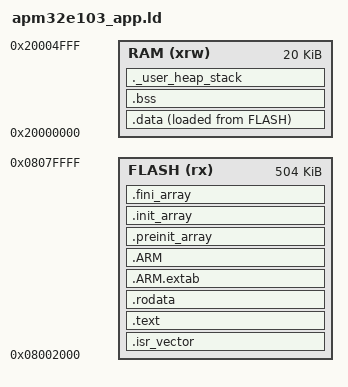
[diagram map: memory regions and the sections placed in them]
/*!
 * @file       apm32e103_app.ld
 *
 * @brief      Linker script for APM32E103CE Device
 *             Application starts at 0x08002000 (compatible with BlackMagic DFU bootloader)
 *             512KB Flash (504KB available for app), 128KB RAM
 *
 * @note       Bootloader: 0x08000000 - 0x08002000 (8KB)
 *             Application: 0x08002000 - 0x08080000 (504KB)
 */

/* Entry Point */
ENTRY(Reset_Handler)

/* Highest address of the user mode stack */
_estack = 0x20020000;    /* end of RAM (128KB) */
/* BlackMagic DFU validity check expects the initial MSP to be within 0x20000000-0x2001FFFF. */
_end_stack = 0x20004FFC; /* startup_apm32e10x_hd.S uses this value in vector table */

/* Generate a link error if heap and stack don't fit into RAM */
_Min_Heap_Size = 0x200;      /* required amount of heap  */
_Min_Stack_Size = 0x400;     /* required amount of stack */

/* Specify the memory areas */
MEMORY
{
  /* Application Flash starting at 0x08002000 (after DFU bootloader) */
  FLASH (rx)      : ORIGIN = 0x08002000, LENGTH = 504K
  RAM (xrw)       : ORIGIN = 0x20000000, LENGTH = 20K
}

/* Define output sections */
SECTIONS
{
  /* The startup code goes first into FLASH */
  .isr_vector :
  {
    . = ALIGN(4);
    /* BlackMagic DFU validates app by checking MSP word at app base address. */
    KEEP(*(.apm32_isr_vector))
    KEEP(*(.isr_vector)) /* Startup code */
    . = ALIGN(4);
  } >FLASH

  /* The program code and other data goes into FLASH */
  .text :
  {
    . = ALIGN(4);
    *(.text)           /* .text sections (code) */
    *(.text*)          /* .text* sections (code) */
    *(.glue_7)         /* glue arm to thumb code */
    *(.glue_7t)        /* glue thumb to arm code */
    *(.eh_frame)

    KEEP (*(.init))
    KEEP (*(.fini))

    . = ALIGN(4);
    _etext = .;        /* define a global symbols at end of code */
  } >FLASH

  /* Constant data goes into FLASH */
  .rodata :
  {
    . = ALIGN(4);
    *(.rodata)         /* .rodata sections (constants, strings, etc.) */
    *(.rodata*)        /* .rodata* sections (constants, strings, etc.) */
    . = ALIGN(4);
  } >FLASH

  .ARM.extab   : { *(.ARM.extab* .gnu.linkonce.armextab.*) } >FLASH
  .ARM : {
    __exidx_start = .;
    *(.ARM.exidx*)
    __exidx_end = .;
  } >FLASH

  .preinit_array     :
  {
    PROVIDE_HIDDEN (__preinit_array_start = .);
    KEEP (*(.preinit_array*))
    PROVIDE_HIDDEN (__preinit_array_end = .);
  } >FLASH
  
  .init_array :
  {
    PROVIDE_HIDDEN (__init_array_start = .);
    KEEP (*(SORT(.init_array.*)))
    KEEP (*(.init_array*))
    PROVIDE_HIDDEN (__init_array_end = .);
  } >FLASH
  
  .fini_array :
  {
    PROVIDE_HIDDEN (__fini_array_start = .);
    KEEP (*(SORT(.fini_array.*)))
    KEEP (*(.fini_array*))
    PROVIDE_HIDDEN (__fini_array_end = .);
  } >FLASH

  /* used by the startup to initialize data */
  _sidata = LOADADDR(.data);
  _start_address_init_data = LOADADDR(.data);

  /* Initialized data sections goes into RAM, load LMA copy after code */
  .data : 
  {
    . = ALIGN(4);
    _sdata = .;        /* create a global symbol at data start */
    _start_address_data = .;
    *(.data)           /* .data sections */
    *(.data*)          /* .data* sections */

    . = ALIGN(4);
    _edata = .;        /* define a global symbol at data end */
    _end_address_data = .;
  } >RAM AT> FLASH

  
  /* Uninitialized data section */
  . = ALIGN(4);
  .bss :
  {
    /* This is used by the startup in order to initialize the .bss secion */
    _sbss = .;         /* define a global symbol at bss start */
    _start_address_bss = .;
    __bss_start__ = _sbss;
    *(.bss)
    *(.bss*)
    *(COMMON)

    . = ALIGN(4);
    _ebss = .;         /* define a global symbol at bss end */
    _end_address_bss = .;
    __bss_end__ = _ebss;
  } >RAM

  /* User_heap_stack section, used to check that there is enough RAM left */
  ._user_heap_stack :
  {
    . = ALIGN(8);
    PROVIDE ( end = . );
    PROVIDE ( _end = . );
    . = . + _Min_Heap_Size;
    . = . + _Min_Stack_Size;
    . = ALIGN(8);
  } >RAM

  

  /* Remove information from the standard libraries */
  /DISCARD/ :
  {
    libc.a ( * )
    libm.a ( * )
    libgcc.a ( * )
  }

  .ARM.attributes 0 : { *(.ARM.attributes) }
}
